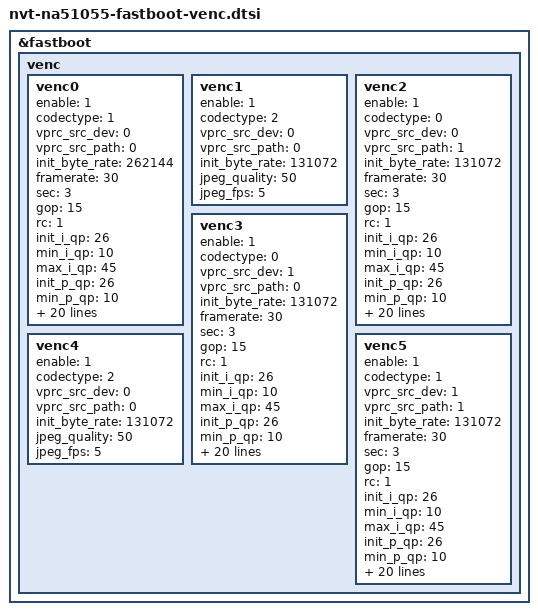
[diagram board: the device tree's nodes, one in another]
&fastboot {
	venc {
		venc0 {
			enable = <1>;
			codectype = <1>;
			vprc_src_dev = <0>;
			vprc_src_path = <0>;
			init_byte_rate = <262144>;
			framerate = <30>;
			sec = <3>;
			gop = <15>;
			rc = <1>;
			init_i_qp = <26>;
			min_i_qp = <10>;
			max_i_qp = <45>;
			init_p_qp = <26>;
			min_p_qp = <10>;
			max_p_qp = <45>;
			rc_byte_rate = <262144>;
			static_time = <4>;
			ip_weight = <0x0>;
			key_p_period = <0>;
			kp_weight = <0x0>;
			p2_weight = <0x0>;
			p3_weight = <0x0>;
			lt_weight = <0x0>;
			motion_aq_str = <0x0>;
			svc_weight_mode = <0x0>;
			svc_layer = <0>;
			ltr_interval = <0>;
			d2d = <0>;
			gdc = <0>;
			colmv = <1>;
			qualitylv = <0>;
			isp_id = <0>;
			h26x_rotate = <0>;
			srcout_size = <0>;
		};

		venc1 {
			enable = <1>;
			codectype = <2>;
			vprc_src_dev = <0>;
			vprc_src_path = <0>;
			init_byte_rate = <131072>;
			jpeg_quality = <50>;
			jpeg_fps = <5>;
		};

		venc2 {
			enable = <1>;
			codectype = <0>;
			vprc_src_dev = <0>;
			vprc_src_path = <1>;
			init_byte_rate = <131072>;
			framerate = <30>;
			sec = <3>;
			gop = <15>;
			rc = <1>;
			init_i_qp = <26>;
			min_i_qp = <10>;
			max_i_qp = <45>;
			init_p_qp = <26>;
			min_p_qp = <10>;
			max_p_qp = <45>;
			rc_byte_rate = <131072>;
			static_time = <4>;
			ip_weight = <0x0>;
			key_p_period = <0>;
			kp_weight = <0x0>;
			p2_weight = <0x0>;
			p3_weight = <0x0>;
			lt_weight = <0x0>;
			motion_aq_str = <0x0>;
			svc_weight_mode = <0x0>;
			svc_layer = <0>;
			ltr_interval = <0>;
			d2d = <0>;
			gdc = <1>;
			colmv = <1>;
			qualitylv = <0>;
			isp_id = <0>;
			h26x_rotate = <0>;
			srcout_size = <0>;
		};

		venc3 {
			enable = <1>;
			codectype = <0>;
			vprc_src_dev = <1>;
			vprc_src_path = <0>;
			init_byte_rate = <131072>;
			framerate = <30>;
			sec = <3>;
			gop = <15>;
			rc = <1>;
			init_i_qp = <26>;
			min_i_qp = <10>;
			max_i_qp = <45>;
			init_p_qp = <26>;
			min_p_qp = <10>;
			max_p_qp = <45>;
			rc_byte_rate = <131072>;
			static_time = <4>;
			ip_weight = <0x0>;
			key_p_period = <0>;
			kp_weight = <0x0>;
			p2_weight = <0x0>;
			p3_weight = <0x0>;
			lt_weight = <0x0>;
			motion_aq_str = <0x0>;
			svc_weight_mode = <0x0>;
			svc_layer = <0>;
			ltr_interval = <0>;
			d2d = <0>;
			gdc = <1>;
			colmv = <1>;
			qualitylv = <0>;
			isp_id = <1>;
			h26x_rotate = <0>;
			srcout_size = <0>;
		};

		venc4 {
			enable = <1>;
			codectype = <2>;
			vprc_src_dev = <0>;
			vprc_src_path = <0>;
			init_byte_rate = <131072>;
			jpeg_quality = <50>;
			jpeg_fps = <5>;
		};

		venc5 {
			enable = <1>;
			codectype = <1>;
			vprc_src_dev = <1>;
			vprc_src_path = <1>;
			init_byte_rate = <131072>;
			framerate = <30>;
			sec = <3>;
			gop = <15>;
			rc = <1>;
			init_i_qp = <26>;
			min_i_qp = <10>;
			max_i_qp = <45>;
			init_p_qp = <26>;
			min_p_qp = <10>;
			max_p_qp = <45>;
			rc_byte_rate = <131072>;
			static_time = <4>;
			ip_weight = <0x0>;
			key_p_period = <0>;
			kp_weight = <0x0>;
			p2_weight = <0x0>;
			p3_weight = <0x0>;
			lt_weight = <0x0>;
			motion_aq_str = <0x0>;
			svc_weight_mode = <0x0>;
			svc_layer = <0>;
			ltr_interval = <0>;
			d2d = <0>;
			gdc = <0>;
			colmv = <1>;
			qualitylv = <0>;
			isp_id = <1>;
			h26x_rotate = <0>;
			srcout_size = <0>;
		};

	};
};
